# XMC1200 register map
Vendor: Infineon; File version: 1.2.2 (Reference Manual v1.2)
CPU: CM0 r0p0, little endian, no MPU, no FPU, 2 interrupt priority bits
Registers are 32-bit, read-write, reset 0x0 unless marked. A register's access mark holds for its fields unless they carry their own. Offsets are from the block's base; [hi:lo] are bit positions; {n}, {i} and the like mark numbered series.

## PAU — PAU Unit
Base 0x40000000
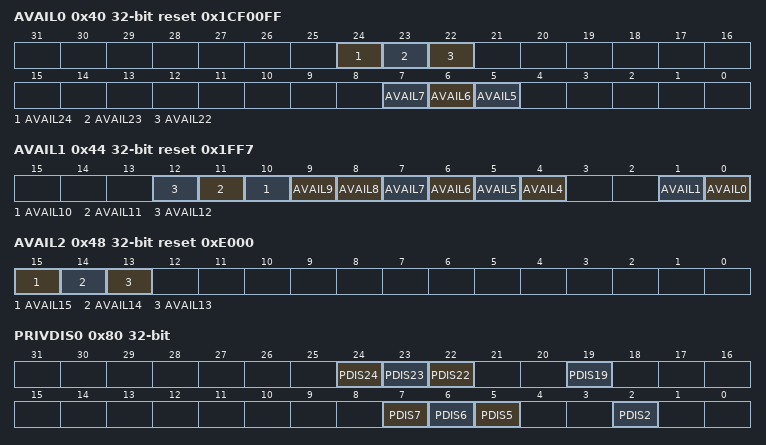
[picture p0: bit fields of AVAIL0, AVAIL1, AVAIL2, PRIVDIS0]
0x40 AVAIL0 ro reset 0x1CF00FF — Peripheral Availability Register 0
  [24] AVAIL24 — Port 0 Availability Flag
    0=Port 2 is not available; 1=Port 2 is available
  [23] AVAIL23 — Port 1 Availability Flag
    0=Port 1 is not available; 1=Port 1 is available
  [22] AVAIL22 — Port 0 Availability Flag
    0=Port 0 is not available; 1=Port 0 is available
  [7] AVAIL7 — RAM Block 3 Availability Flag
    0=RAM block 3 is not available; 1=RAM block 3 is available
  [6] AVAIL6 — RAM Block 2 Availability Flag
    0=RAM block 2 is not available; 1=RAM block 2 is available
  [5] AVAIL5 — RAM Block 1 Availability Flag
    0=RAM block 1 is not available; 1=RAM block 1 is available
0x44 AVAIL1 ro reset 0x1FF7 — Peripheral Availability Register 1
  [n] AVAIL{n} (n=9..12) — CC{n+31} Availability Flag
    0=CC{n+31} is not available; 1=CC{n+31} is available
  [8] AVAIL8 — SHS0 Availability Flag
    0=SHS0 is not available; 1=SHS0 is available
  [7] AVAIL7 — VADC0 Group 1 SFRs Availability Flag
    0=VADC0 Group 1 SFRs are not available; 1=VADC0 Group 1 SFRs are available
  [6] AVAIL6 — VADC0 Group 0 SFRs Availability Flag
    0=VADC0 Group 0 SFRs are not available; 1=VADC0 Group 0 SFRs are available
  [5] AVAIL5 — VADC0 Basic SFRs Availability Flag
    0=VADC0 Basic SFRs are not available; 1=VADC0 Basic SFRs are available
  [4] AVAIL4 — PRNG Availability Flag
    0=PRNG is not available; 1=PRNG is available
  [1] AVAIL1 — USIC0 Channel 1 Availability Flag
    0=USIC0 Channel 1 is not available; 1=USIC0 Channel 1 is available
  [0] AVAIL0 — USIC0 Channel 0 Availability Flag
    0=USIC0 Channel 0 is not available; 1=USIC0 Channel 0 is available
0x48 AVAIL2 ro reset 0xE000 — Peripheral Availability Register 2
  [15] AVAIL15 — BCCU0 Availability Flag
    0=BCCU0 is not available; 1=BCCU0 is available
  [14] AVAIL14 — LEDTS1 Sync Slave Availability Flag
    0=LEDTS0 Sync Slave is not available; 1=LEDTS0 Sync Slave is available
  [13] AVAIL13 — LEDTS0 Sync Master Availability Flag
    0=LEDTS0 Sync Master is not available; 1=LEDTS0 Sync Master is available
0x80 PRIVDIS0 — Peripheral Privilege Access Register 0
  [24] PDIS24 — Port 2 Privilege Disable Flag
    0=Port 2 is accessible; 1=Port 2 is not accessible
  [23] PDIS23 — Port 1 Privilege Disable Flag
    0=Port 1 is accessible; 1=Port 1 is not accessible
  [22] PDIS22 — Port 0 Privilege Disable Flag
    0=Port 0 is accessible; 1=Port 0 is not accessible
  [19] PDIS19 — WDT Privilege Disable Flag
    0=WDT is accessible; 1=WDT is not accessible
  [7] PDIS7 — RAM Block 3 Privilege Disable Flag
    0=RAM Block 3 is accessible; 1=RAM Block 3 is not accessible
  [6] PDIS6 — RAM Block 2 Privilege Disable Flag
    0=RAM Block 2 is accessible; 1=RAM Block 2 is not accessible
  [5] PDIS5 — RAM Block 1 Privilege Disable Flag
    0=RAM Block 1 is accessible; 1=RAM Block 1 is not accessible
  [2] PDIS2 — Flash SFRs Privilege Disable Flag
    0=Flash SFRs are accessible; 1=Flash SFRs are not accessible
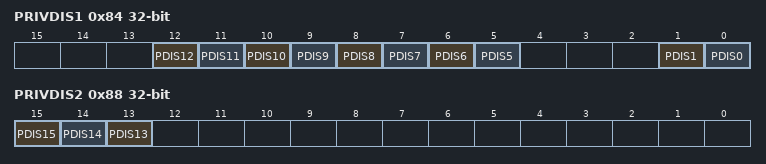
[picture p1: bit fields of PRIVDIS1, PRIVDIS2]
0x84 PRIVDIS1 — Peripheral Privilege Access Register 1
  [12] PDIS12 — CC43 Privilege Disable Flag
    0=CC43 is accessible; 1=CC43 is not accessible
  [11] PDIS11 — CC42 Privilege Disable Flag
    0=CC42 is accessible; 1=CC42 is not accessible
  [10] PDIS10 — CC41 Privilege Disable Flag
    0=CC41 is accessible; 1=CC41 is not accessible
  [9] PDIS9 — CC40 and CCU40 Kernel SFRs Privilege Disable Flag
    0=CC40 and CCU40 Kernel SFRs are accessible; 1=CC40 and CCU40 Kernel SFRs are not accessible
  [8] PDIS8 — SHS0 Privilege Disable Flag
    0=SHS0 is accessible; 1=SHS0 is not accessible
  [7] PDIS7 — VADC0 Group 1 SFRs Privilege Disable Flag
    0=VADC0 Group 1 SFRs are accessible; 1=VADC0 Group 1 SFRs are not accessible
  [6] PDIS6 — VADC0 Group 0 SFRs Privilege Disable Flag
    0=VADC0 Group 0 SFRs are accessible; 1=VADC0 Group 0 SFRs are not accessible
  [5] PDIS5 — VADC0 Basic SFRs Privilege Disable Flag
    0=VADC0 Basic SFRs are accessible; 1=VADC0 Basic SFRs are not accessible
  [1] PDIS1 — USIC0 Channel 1 Privilege Disable Flag
    0=USIC0 Channel 1 is accessible; 1=USIC0 Channel 1 is not accessible
  [0] PDIS0 — USIC0 Channel 0 Privilege Disable Flag
    0=USIC0 Channel 0 is accessible; 1=USIC0 Channel 0 is not accessible
0x88 PRIVDIS2 — Peripheral Privilege Access Register 2
  [15] PDIS15 — BCCU0 Privilege Disable Flag
    0=BCCU0 is accessible; 1=BCCU0 is not accessible
  [14] PDIS14 — LEDTS1 Sync Slave Privilege Disable Flag
    0=LEDTS1 Sync Slave is accessible; 1=LEDTS1 Sync Slave is not accessible
  [13] PDIS13 — LEDTS0 Sync Master Privilege Disable Flag
    0=LEDTS0 Sync Master is accessible; 1=LEDTS0 Sync Master is not accessible
0x400 ROMSIZE ro reset 0xB00
  [13:8] ADDR — ROM Size
0x404 FLSIZE ro reset 0x33000 — Flash Size Register
  [17:12] ADDR — Flash Size
0x410 RAM0SIZE ro reset 0x1000
  [12:8] ADDR — RAM0 Size

## Notices in the file
Copyright (C) 2012 Infineon Technologies AG. All rights reserved.
Infineon Technologies AG (Infineon) is supplying this software for use with
Infineon's microcontrollers.  This file can be freely distributed within
development tools that are supporting such microcontrollers.
THIS SOFTWARE IS PROVIDED "AS IS".  NO WARRANTIES, WHETHER EXPRESS, IMPLIED
OR STATUTORY, INCLUDING, BUT NOT LIMITED TO, IMPLIED WARRANTIES OF
MERCHANTABILITY AND FITNESS FOR A PARTICULAR PURPOSE APPLY TO THIS SOFTWARE.
INFINEON SHALL NOT, IN ANY CIRCUMSTANCES, BE LIABLE FOR SPECIAL, INCIDENTAL,
OR CONSEQUENTIAL DAMAGES, FOR ANY REASON WHATSOEVER.
